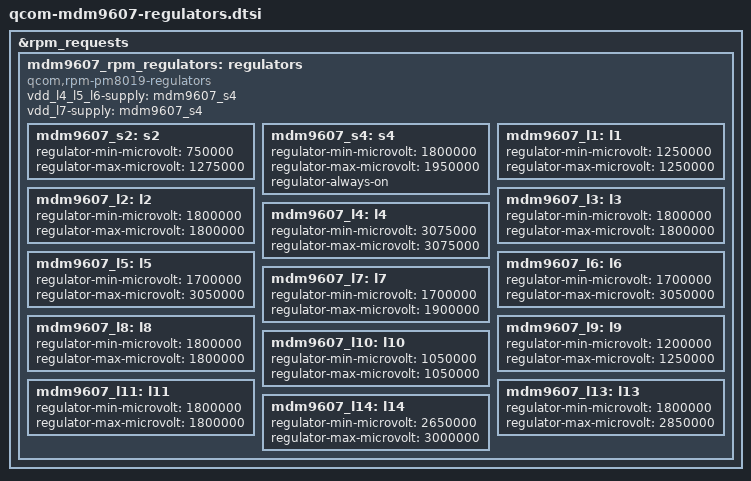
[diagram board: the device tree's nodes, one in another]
// SPDX-License-Identifier: GPL-2.0-only
/*
 * MDM9607 RPM-SMD regulator setup using PM8019 PMIC.
 *
 * Rails NOT listed here (managed by rpmpd power domains instead):
 *   s1  - unused / disabled in original BSP
 *   s3  - VDDCX (rpmpd cx_s3a_lvl, corner-voted)
 *   l12 - VDDMX (rpmpd mx_l12a_lvl, corner-voted)
 */

&rpm_requests {
	mdm9607_rpm_regulators: regulators {
		compatible = "qcom,rpm-pm8019-regulators";
		vdd_l4_l5_l6-supply = <&mdm9607_s4>;
		vdd_l7-supply = <&mdm9607_s4>;

		mdm9607_s2: s2 {
			regulator-min-microvolt = <750000>;
			regulator-max-microvolt = <1275000>;
		};

		mdm9607_s4: s4 {
			regulator-min-microvolt = <1800000>;
			regulator-max-microvolt = <1950000>;
			regulator-always-on;
		};

		mdm9607_l1: l1 {
			regulator-min-microvolt = <1250000>;
			regulator-max-microvolt = <1250000>;
		};

		mdm9607_l2: l2 {
			regulator-min-microvolt = <1800000>;
			regulator-max-microvolt = <1800000>;
		};

		mdm9607_l3: l3 {
			regulator-min-microvolt = <1800000>;
			regulator-max-microvolt = <1800000>;
		};

		mdm9607_l4: l4 {
			regulator-min-microvolt = <3075000>;
			regulator-max-microvolt = <3075000>;
		};

		mdm9607_l5: l5 {
			regulator-min-microvolt = <1700000>;
			regulator-max-microvolt = <3050000>;
		};

		mdm9607_l6: l6 {
			regulator-min-microvolt = <1700000>;
			regulator-max-microvolt = <3050000>;
		};

		mdm9607_l7: l7 {
			regulator-min-microvolt = <1700000>;
			regulator-max-microvolt = <1900000>;
		};

		mdm9607_l8: l8 {
			regulator-min-microvolt = <1800000>;
			regulator-max-microvolt = <1800000>;
		};

		mdm9607_l9: l9 {
			regulator-min-microvolt = <1200000>;
			regulator-max-microvolt = <1250000>;
		};

		mdm9607_l10: l10 {
			regulator-min-microvolt = <1050000>;
			regulator-max-microvolt = <1050000>;
		};

		mdm9607_l11: l11 {
			regulator-min-microvolt = <1800000>;
			regulator-max-microvolt = <1800000>;
		};

		mdm9607_l13: l13 {
			regulator-min-microvolt = <1800000>;
			regulator-max-microvolt = <2850000>;
		};

		mdm9607_l14: l14 {
			regulator-min-microvolt = <2650000>;
			regulator-max-microvolt = <3000000>;
		};
	};
};
